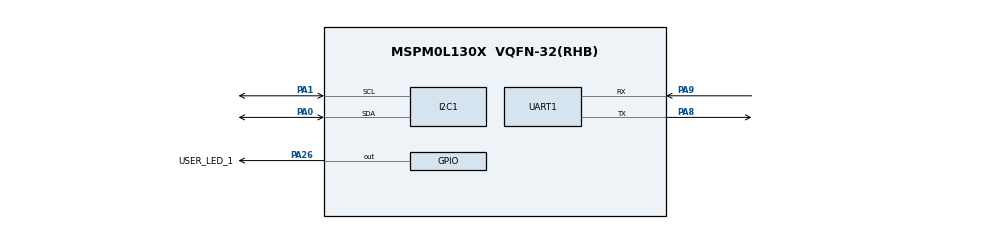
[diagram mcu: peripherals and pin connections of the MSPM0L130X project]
/**
 * @cliArgs --device "MSPM0L130X" --part "Default" --package "VQFN-32(RHB)" --product "mspm0_sdk@2.05.00.05"
 * @versions {"tool":"1.24.0+4110"}
 */

/**
 * Import the modules used in this configuration.
 */
const Board  = scripting.addModule("/ti/driverlib/Board");
const GPIO   = scripting.addModule("/ti/driverlib/GPIO", {}, false);
const GPIO1  = GPIO.addInstance();
const GPIO2  = GPIO.addInstance();
const I2C    = scripting.addModule("/ti/driverlib/I2C", {}, false);
const I2C1   = I2C.addInstance();
const SYSCTL = scripting.addModule("/ti/driverlib/SYSCTL");
const UART   = scripting.addModule("/ti/driverlib/UART", {}, false);
const UART1  = UART.addInstance();

/**
 * Write custom configuration values to the imported modules.
 */
Board.configureUnused = true;

GPIO1.$name                                 = "GPIO_LEDS";
GPIO1.port                                  = "PORTA";
GPIO1.associatedPins[0].$name               = "USER_LED_1";
GPIO1.associatedPins[0].assignedPortSegment = "Upper";
GPIO1.associatedPins[0].assignedPin         = "26";
GPIO1.associatedPins[0].pin.$assign         = "PA26";

GPIO2.$name                         = "GPIO_TESTS";
GPIO2.port                          = "PORTA";
GPIO2.associatedPins[0].$name       = "TESTPIN";
GPIO2.associatedPins[0].assignedPin = "17";

I2C1.$name                             = "I2C";
I2C1.basicControllerBusSpeed           = 400000;
I2C1.advControllerTXFIFOTRIG           = "BYTES_1";
I2C1.basicTargetAddress                = 0x48;
I2C1.basicEnableTarget                 = true;
I2C1.advAnalogGlitchFilter             = "DISABLED";
I2C1.peripheral.$assign                = "I2C0";
I2C1.peripheral.sdaPin.$assign         = "PA0";
I2C1.peripheral.sclPin.$assign         = "PA1";
I2C1.sdaPinConfig.$name                = "ti_driverlib_gpio_GPIOPinGeneric0";
I2C1.sdaPinConfig.hideOutputInversion  = scripting.forceWrite(false);
I2C1.sdaPinConfig.onlyInternalResistor = scripting.forceWrite(false);
I2C1.sdaPinConfig.passedPeripheralType = scripting.forceWrite("Digital");
I2C1.sclPinConfig.$name                = "ti_driverlib_gpio_GPIOPinGeneric1";
I2C1.sclPinConfig.hideOutputInversion  = scripting.forceWrite(false);
I2C1.sclPinConfig.onlyInternalResistor = scripting.forceWrite(false);
I2C1.sclPinConfig.passedPeripheralType = scripting.forceWrite("Digital");

SYSCTL.powerPolicy = "STOP0";
SYSCTL.clockTreeEn = true;

UART1.$name                    = "UART_0";
UART1.targetBaudRate           = 115200;
UART1.peripheral.rxPin.$assign = "PA9";
UART1.peripheral.txPin.$assign = "PA8";
UART1.txPinConfig.$name        = "ti_driverlib_gpio_GPIOPinGeneric2";
UART1.rxPinConfig.$name        = "ti_driverlib_gpio_GPIOPinGeneric3";

/**
 * Pinmux solution for unlocked pins/peripherals. This ensures that minor changes to the automatic solver in a future
 * version of the tool will not impact the pinmux you originally saw.  These lines can be completely deleted in order to
 * re-solve from scratch.
 */
Board.peripheral.$suggestSolution            = "DEBUGSS";
Board.peripheral.swclkPin.$suggestSolution   = "PA20";
Board.peripheral.swdioPin.$suggestSolution   = "PA19";
GPIO2.associatedPins[0].pin.$suggestSolution = "PA17/OPA1.IN0-";
UART1.peripheral.$suggestSolution            = "UART0";
